# STM32F303 register map
File version: 1.9
CPU: CM4 r1p0, little endian, MPU, FPU, 3 interrupt priority bits
Registers are 32-bit, read-write, reset 0x0 unless marked. A register's access mark holds for its fields unless they carry their own. Offsets are from the block's base; [hi:lo] are bit positions; {n}, {i} and the like mark numbered series.

## EXTI — External interrupt/event controller
Base 0x40010400
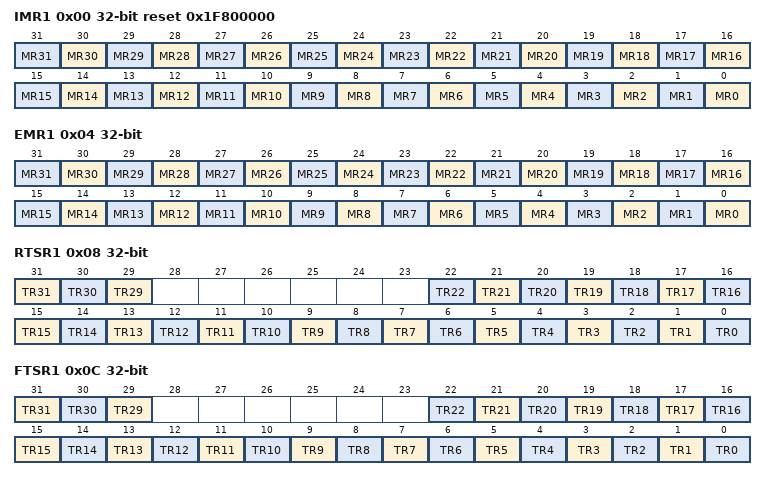
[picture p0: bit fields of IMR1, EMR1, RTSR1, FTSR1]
0x00 IMR1 reset 0x1F800000 — Interrupt mask register
  [n] MR{n} (n=0..31) — Interrupt Mask on line {n}
0x04 EMR1 — Event mask register
  [n] MR{n} (n=0..31) — Event Mask on line {n}
0x08 RTSR1 — Rising Trigger selection register
  [31] TR31 — Rising trigger event configuration of line 31
  [30] TR30 — Rising trigger event configuration of line 30
  [29] TR29 — Rising trigger event configuration of line 29
  [n] TR{n} (n=0..22) — Rising trigger event configuration of line {n}
0x0C FTSR1 — Falling Trigger selection register
  [31] TR31 — Falling trigger event configuration of line 31
  [30] TR30 — Falling trigger event configuration of line 30.
  [29] TR29 — Falling trigger event configuration of line 29
  [n] TR{n} (n=0..22) — Falling trigger event configuration of line {n}
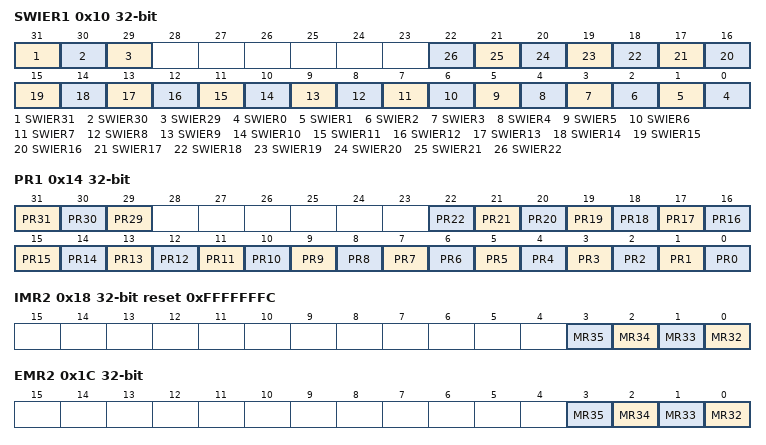
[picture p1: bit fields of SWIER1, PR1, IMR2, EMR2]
0x10 SWIER1 — Software interrupt event register
  [31] SWIER31 — Software Interrupt on line 319
  [30] SWIER30 — Software Interrupt on line 309
  [29] SWIER29 — Software Interrupt on line 29
  [n] SWIER{n} (n=0..22) — Software Interrupt on line {n}
0x14 PR1 — Pending register
  [31] PR31 — Pending bit 31
  [30] PR30 — Pending bit 30
  [29] PR29 — Pending bit 29
  [n] PR{n} (n=0..22) — Pending bit {n}
0x18 IMR2 reset 0xFFFFFFFC — Interrupt mask register
  [n-32] MR{n} (n=32..35) — Interrupt Mask on external/internal line {n}
0x1C EMR2 — Event mask register
  [n-32] MR{n} (n=32..35) — Event mask on external/internal line {n}
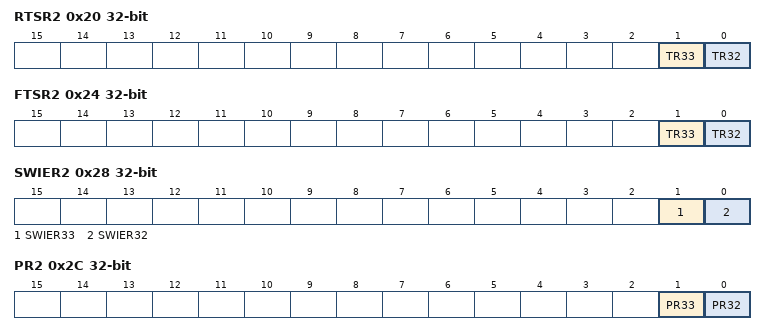
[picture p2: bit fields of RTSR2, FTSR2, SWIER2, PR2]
0x20 RTSR2 — Rising Trigger selection register
  [1] TR33 — Rising trigger event configuration bit of line 33
  [0] TR32 — Rising trigger event configuration bit of line 32
0x24 FTSR2 — Falling Trigger selection register
  [1] TR33 — Falling trigger event configuration bit of line 33
  [0] TR32 — Falling trigger event configuration bit of line 32
0x28 SWIER2 — Software interrupt event register
  [1] SWIER33 — Software interrupt on line 33
  [0] SWIER32 — Software interrupt on line 32
0x2C PR2 — Pending register
  [1] PR33 — Pending bit on line 33
  [0] PR32 — Pending bit on line 32

## PWR — Power control
Base 0x40007000
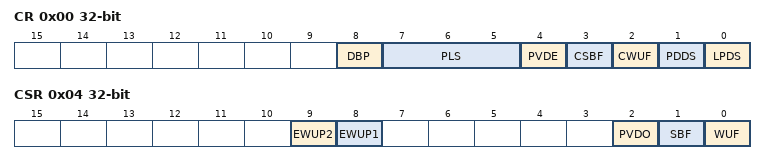
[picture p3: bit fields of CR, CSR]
0x00 CR — power control register
  [8] DBP — Disable backup domain write protection
  [7:5] PLS — PVD level selection
  [4] PVDE — Power voltage detector enable
  [3] CSBF — Clear standby flag
  [2] CWUF — Clear wakeup flag
  [1] PDDS — Power down deepsleep
  [0] LPDS — Low-power deep sleep
0x04 CSR access per field — power control/status register
  [9] EWUP2 rw — Enable WKUP2 pin
  [8] EWUP1 rw — Enable WKUP1 pin
  [2] PVDO ro — PVD output
  [1] SBF ro — Standby flag
  [0] WUF ro — Wakeup flag

## USB_FS — Universal serial bus full-speed device interface
Base 0x40005C00
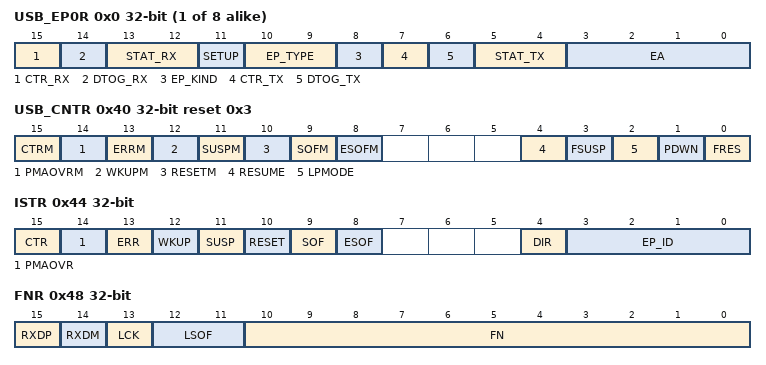
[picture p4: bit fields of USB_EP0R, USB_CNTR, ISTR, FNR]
{0x0+4i} USB_EP{i}R access per field (i=0..7) — endpoint {i} register
  [15] CTR_RX rw — Correct transfer for reception
  [14] DTOG_RX rw — Data Toggle, for reception transfers
  [13:12] STAT_RX rw — Status bits, for reception transfers
  [11] SETUP ro — Setup transaction completed
  [10:9] EP_TYPE rw — Endpoint type
  [8] EP_KIND rw — Endpoint kind
  [7] CTR_TX rw — Correct Transfer for transmission
  [6] DTOG_TX rw — Data Toggle, for transmission transfers
  [5:4] STAT_TX rw — Status bits, for transmission transfers
  [3:0] EA rw — Endpoint address
0x40 USB_CNTR reset 0x3 — control register
  [15] CTRM — Correct transfer interrupt mask
  [14] PMAOVRM — Packet memory area over / underrun interrupt mask
  [13] ERRM — Error interrupt mask
  [12] WKUPM — Wakeup interrupt mask
  [11] SUSPM — Suspend mode interrupt mask
  [10] RESETM — USB reset interrupt mask
  [9] SOFM — Start of frame interrupt mask
  [8] ESOFM — Expected start of frame interrupt mask
  [4] RESUME — Resume request
  [3] FSUSP — Force suspend
  [2] LPMODE — Low-power mode
  [1] PDWN — Power down
  [0] FRES — Force USB Reset
0x44 ISTR access per field — interrupt status register
  [15] CTR ro — Correct transfer
  [14] PMAOVR rw — Packet memory area over / underrun
  [13] ERR rw — Error
  [12] WKUP rw — Wakeup
  [11] SUSP rw — Suspend mode request
  [10] RESET rw — reset request
  [9] SOF rw — start of frame
  [8] ESOF rw — Expected start frame
  [4] DIR ro — Direction of transaction
  [3:0] EP_ID ro — Endpoint Identifier
0x48 FNR ro — frame number register
  [15] RXDP — Receive data + line status
  [14] RXDM — Receive data - line status
  [13] LCK — Locked
  [12:11] LSOF — Lost SOF
  [10:0] FN — Frame number
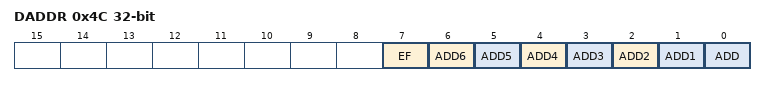
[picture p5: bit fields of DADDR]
0x4C DADDR — device address
  [7] EF — Enable function
  [n] ADD{n} (n=1..6) — Device address
  [0] ADD — Device address
0x50 BTABLE — Buffer table address
  [15:3] BTABLE — Buffer table
